# DA1469x register map
Vendor: Dialog; Series: DA1469x; File version: 1.2
CPU: CM33 r1p0, little endian, no MPU, FPU, 3 interrupt priority bits
Registers are 32-bit, read-write, reset 0x0 unless marked. A register's access mark holds for its fields unless they carry their own. Offsets are from the block's base; [hi:lo] are bit positions; {n}, {i} and the like mark numbered series.

## CRG_TOP — CRG_TOP registers
Base 0x50000000
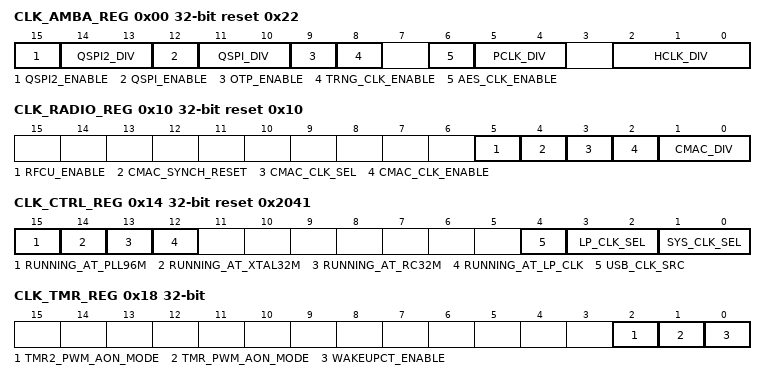
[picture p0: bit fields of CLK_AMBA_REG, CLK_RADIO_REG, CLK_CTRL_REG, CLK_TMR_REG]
0x00 CLK_AMBA_REG reset 0x22 — HCLK, PCLK, divider and clock gates
  [15] QSPI2_ENABLE — Clock enable for QSPI RAM controller
  [14:13] QSPI2_DIV — QSPI divider 00 = divide by 1 01 = divide by 2 10 = divide by 4 11 = divide by 8
  [12] QSPI_ENABLE — Clock enable for QSPI controller
  [11:10] QSPI_DIV — QSPI divider 00 = divide by 1 01 = divide by 2 10 = divide by 4 11 = divide by 8
  [9] OTP_ENABLE — Clock enable for OTP controller
  [8] TRNG_CLK_ENABLE — Clock enable for TRNG block
  [6] AES_CLK_ENABLE — Clock enable for AES crypto block
  [5:4] PCLK_DIV — APB interface clock, Cascaded with HCLK: 00 = divide hclk by 1 01 = divide hclk by 2 10 = divide hclk by 4 11 = divide hclk by 8
  [2:0] HCLK_DIV — AHB interface and microprocessor clock. Source clock divided by: 000 = divide hclk by 1 001 = divide hclk by 2 010 = divide hclk by 4 011 = divide hclk by 8 1xx = divide hclk by 16
0x10 CLK_RADIO_REG reset 0x10 — Radio PLL control register
  [5] RFCU_ENABLE — Enable the RF control Unit clock
  [4] CMAC_SYNCH_RESET — Force synchronous reset to CMAC core and Sleep Timer. Its effective only when both Radio and Timer Power Domains are powered and the clocks are enabled. CMAC CPU and CMAC registers, including the retained ones, will be reset. It should be kept in reset for enough time to make sure that it will be captured by CMAC, Low Power and APB clocks.
  [3] CMAC_CLK_SEL — Selects the clock source 1 = DIV1 clock 0 = DIVN clock
  [2] CMAC_CLK_ENABLE — Enables the clock
  [1:0] CMAC_DIV — Division factor for CMAC 0x0 = divide by 1 0x1 = divide by 2 0x2 = divide by 4 0x3 = divide by 8
0x14 CLK_CTRL_REG reset 0x2041 — Clock control register
  [15] RUNNING_AT_PLL96M ro — Indicates that the PLL96MHz clock is used as clock, and may not be switched off
  [14] RUNNING_AT_XTAL32M ro — Indicates that the XTAL32M clock is used as clock, and may not be switched off
  [13] RUNNING_AT_RC32M ro — Indicates that the RC32M clock is used as clock
  [12] RUNNING_AT_LP_CLK ro — Indicates that either the LP_CLK is being used as clock
  [4] USB_CLK_SRC — Selects the USB source clock 0 : PLL clock, divided by 2 1 : HCLK
  [3:2] LP_CLK_SEL — Sets the clock source of the LowerPower clock 0x0: RC32K 0x1: RCX 0x2: XTAL32K through the oscillator with an external Crystal. 0x3: XTAL32K through an external square wave generator (set PID of GPIO to FUNC_GPIO)
  [1:0] SYS_CLK_SEL — Selects the clock source. 0x0 : XTAL32M 0x1 : RC32M 0x2 : The Low Power clock is used 0x3 : The PLL96Mhz is used
0x18 CLK_TMR_REG — Clock control for the timers
  [2] TMR2_PWM_AON_MODE — Maps Timer2_pwm onto P1_06. This state is preserved during deep sleep, to allow PWM output on the pad during deep sleep.
  [1] TMR_PWM_AON_MODE — Maps Timer1_pwm onto P1_01 This state is preserved during deep sleep, to allow PWM output on the pad during deep sleep.
  [0] WAKEUPCT_ENABLE — Enables the clock
0x1C CLK_SWITCH2XTAL_REG — Switches clock from RC32M to XTAL32M
  [0] SWITCH2XTAL wo — When writing to this register, the clock switch will happen from RC32M to XTAL32M. If any other clock is selected than RC32M, the selection is discarded.
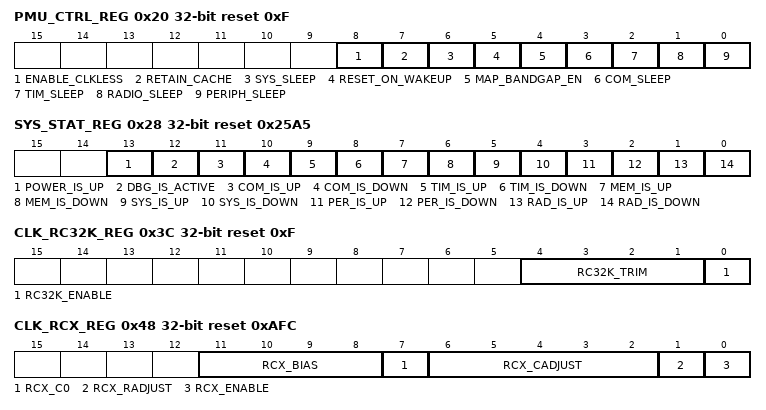
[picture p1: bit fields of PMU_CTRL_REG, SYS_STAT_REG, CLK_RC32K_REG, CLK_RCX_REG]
0x20 PMU_CTRL_REG reset 0xF — Power Management Unit control register
  [8] ENABLE_CLKLESS — Selects the clockless sleep mode. Wakeup is done asynchronously. When set to '1', the lp_clk is stopped during deep sleep, until a wakeup event (not debounced) is detected by the WAKUPCT block. When set to '0', the lp_clk continues running, so the MAC counters keep on running. This mode cannot be combined with regulated sleep, so keep SLEEP_TIMER=0 when using ENABLE_CLKLESS.
  [7] RETAIN_CACHE — Selects the retainability of the cache block during deep sleep. '1' is retainable, '0' is power gated
  [6] SYS_SLEEP — Put the System powerdomain (PD_SYS) in powerdown. If this bit is '1', and there is no pending IRQ in the PDC for the M33, the PD_SYS will be switched off. Wakeup should be handled by the PDC.
  [5] RESET_ON_WAKEUP — Perform a Hardware Reset after waking up. Booter will be started.
  [4] MAP_BANDGAP_EN — Setting this bit will: -map bandgap_enable to P0_25 -map (wokenup OR cmac_slp_timer_expire) to P0_16
  [3] COM_SLEEP — Put the Communications powerdomain (PD_COM) in powerdown
  [2] TIM_SLEEP — Put the Timers Powerdomain (PD_TIM) in powerdown.
  [1] RADIO_SLEEP — Put the digital part of the radio, including CMAC (PD_RAD) in powerdown
  [0] PERIPH_SLEEP — Put the peripherals power domain (PD_PER) in powerdown
0x28 SYS_STAT_REG reset 0x25A5 — System status register
  [13] POWER_IS_UP ro — Indicates that the Startup statemachine is finished, and all power regulation is in order. In UltraFastWakeup mode, the SW needs to wait for this signal before starting any heavy traffic.
  [12] DBG_IS_ACTIVE ro — Indicates that a debugger is attached.
  [11] COM_IS_UP ro — Indicates that PD_COM is functional
  [10] COM_IS_DOWN ro — Indicates that PD_COM is in power down
  [9] TIM_IS_UP ro — Indicates that PD_TIM is functional
  [8] TIM_IS_DOWN ro — Indicates that PD_TIM is in power down
  [7] MEM_IS_UP ro — Indicates that PD_MEM is functional
  [6] MEM_IS_DOWN ro — Indicates that PD_MEM is in power down
  [5] SYS_IS_UP ro — Indicates that PD_SYS is functional
  [4] SYS_IS_DOWN ro — Indicates that PD_SYS is in power down
  [3] PER_IS_UP ro — Indicates that PD_PER is functional
  [2] PER_IS_DOWN ro — Indicates that PD_PER is in power down
  [1] RAD_IS_UP ro — Indicates that PD_RAD is functional
  [0] RAD_IS_DOWN ro — Indicates that PD_RAD is in power down
0x3C CLK_RC32K_REG reset 0xF — 32 kHz RC oscillator register
  [4:1] RC32K_TRIM — 0000 = lowest frequency 0111 = default 1111 = highest frequency
  [0] RC32K_ENABLE — Enables the 32kHz RC oscillator
0x48 CLK_RCX_REG reset 0xAFC — RCX-oscillator control register
  [11:8] RCX_BIAS — LDO bias current. 0x0: minimum 0xF: maximum
  [7] RCX_C0 — Add unit capacitance to RC-time delay.
  [6:2] RCX_CADJUST — Adjust capacitance part of RC-time delay. 0x00: minimum capacitance 0x1F: maximum capacitance
  [1] RCX_RADJUST — Adjust resistance part of RC-time delay. Lower resistance increases power consumption. 0x0: maximum resistance 0x1: minimum resistance
  [0] RCX_ENABLE — Enable the RCX oscillator
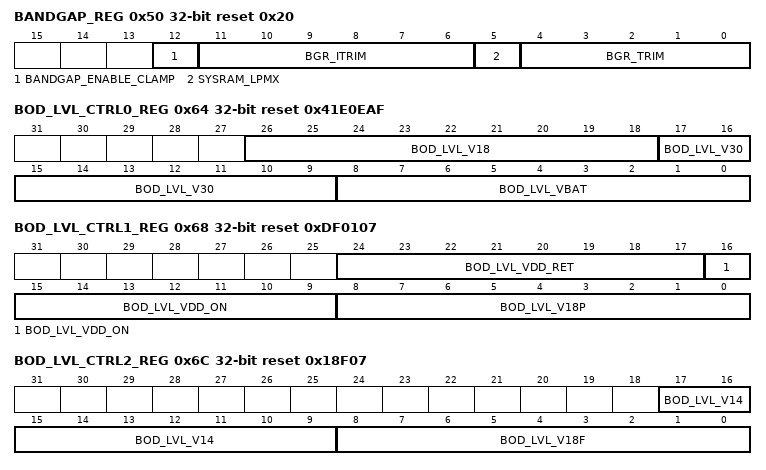
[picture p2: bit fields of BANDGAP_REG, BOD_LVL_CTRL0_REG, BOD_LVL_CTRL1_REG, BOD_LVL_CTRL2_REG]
0x50 BANDGAP_REG reset 0x20 — bandgap trimming
  [12] BANDGAP_ENABLE_CLAMP — Enables a supply clamp inside the bandgap that improves PSRR. Should be enabled by software after cold boot.
  [11:6] BGR_ITRIM — Current trimming for bias
  [5] SYSRAM_LPMX — RAM Transparent Light Sleep (TLS) Core Enable for System RAMs. Assert low to enable the TLS core feature, which will result in lower leakage current. In case VDD is below 0.81V, it is necessary to hold this pin high to maintain data retention.
  [4:0] BGR_TRIM — Trim register for bandgap
0x58 VBUS_IRQ_CLEAR_REG — Clear pending IRQ register
  [15:0] VBUS_IRQ_CLEAR wo — Writing any value to this register will reset the VBUS_IRQ line
0x64 BOD_LVL_CTRL0_REG reset 0x41E0EAF
  [26:18] BOD_LVL_V18 — Brown-out detection level for V18; disable the bod channel before adjusting the level setting. VTH_BOD = 1.2 * (BOD_LVL+1)/192
  [17:9] BOD_LVL_V30 — Brown-out detection level for V30; disable the bod channel before adjusting the level setting. VTH_BOD = 1.2 * (BOD_LVL+1)/192
  [8:0] BOD_LVL_VBAT — Brown-out detection level for VBAT; disable the bod channel before adjusting the level setting. VTH_BOD = 1.5*(1.2 * (BOD_LVL+1)/192)
0x68 BOD_LVL_CTRL1_REG reset 0xDF0107
  [24:17] BOD_LVL_VDD_RET — Brown-out detection level for VDD in sleep; disable the bod channel before adjusting the level setting. VTH_BOD = 1.2 * (BOD_LVL+1)/192
  [16:9] BOD_LVL_VDD_ON — Brown-out detection level for VDD in active; disable the bod channel before adjusting the level setting. VTH_BOD = 1.2 * (BOD_LVL+1)/192
  [8:0] BOD_LVL_V18P — Brown-out detection level for V18P; disable the bod channel before adjusting the level setting. VTH_BOD = 1.2 * (BOD_LVL+1)/192
0x6C BOD_LVL_CTRL2_REG reset 0x18F07
  [17:9] BOD_LVL_V14 — Brown-out detection level for V14; disable the bod channel before adjusting the level setting. VTH_BOD = 1.2 * (BOD_LVL+1)/192
  [8:0] BOD_LVL_V18F — Brown-out detection level for V18F; disable the bod channel before adjusting the level setting. VTH_BOD = 1.2 * (BOD_LVL+1)/192
0x70 P0_PAD_LATCH_REG reset 0x7FFFFFFF (reset mask 0x7FFFFFFF) — Control the state retention of the GPIO ports
  [31:0] P0_LATCH_EN — Direct write to the specific pad_latch_enable signal
0x74 P0_SET_PAD_LATCH_REG (reset mask 0x7FFFFFFF) — Control the state retention of the GPIO ports
  [31:0] P0_SET_LATCH_EN rw-once — Direct Set of the marked bits. Reading returns 0x0.
0x78 P0_RESET_PAD_LATCH_REG (reset mask 0x7FFFFFFF) — Control the state retention of the GPIO ports
  [31:0] P0_RESET_LATCH_EN — Direct Reset of the marked bits. Reading returns 0x0.
0x7C P1_PAD_LATCH_REG reset 0x7FFFFF — Control the state retention of the GPIO ports
  [22:0] P1_LATCH_EN — Direct write to the specific pad_latch_enable signal
0x80 P1_SET_PAD_LATCH_REG — Control the state retention of the GPIO ports
  [22:0] P1_SET_LATCH_EN rw-once — Direct Set of the marked bits. Reading returns 0x0.
0x84 P1_RESET_PAD_LATCH_REG — Control the state retention of the GPIO ports
  [22:0] P1_RESET_LATCH_EN — Direct Reset of the marked bits. Reading returns 0x0.
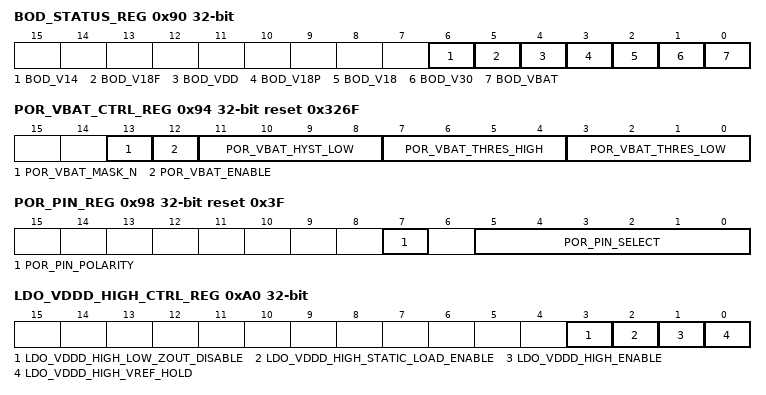
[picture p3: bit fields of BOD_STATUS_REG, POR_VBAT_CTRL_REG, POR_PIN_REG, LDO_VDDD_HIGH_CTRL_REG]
0x90 BOD_STATUS_REG
  [6] BOD_V14 ro — 1: below trigger level (BOD event) 0: above trigger level
  [5] BOD_V18F ro — 1: below trigger level (BOD event) 0: above trigger level
  [4] BOD_VDD ro — 1: below trigger level (BOD event) 0: above trigger level
  [3] BOD_V18P ro — 1: below trigger level (BOD event) 0: above trigger level
  [2] BOD_V18 ro — 1: below trigger level (BOD event) 0: above trigger level
  [1] BOD_V30 ro — 1: below trigger level (BOD event) 0: above trigger level
  [0] BOD_VBAT ro — 1: below trigger level (BOD event) 0: above trigger level
0x94 POR_VBAT_CTRL_REG reset 0x326F — Controls the POR on VBAT
  [13] POR_VBAT_MASK_N — Enables propagation of the generated POR
  [12] POR_VBAT_ENABLE — Enables generation of the POR
  [11:8] POR_VBAT_HYST_LOW — Controls hysteresis of POR. 20mV per step. Must be set to 0x2 when thres_ctrl_low is set to 0xf.
  [7:4] POR_VBAT_THRES_HIGH — High-side (PTAT) threshold contribution: Level --> Threshold 0x0 --> 1.25V 0x1 --> 1.27V 0x2 --> 1.29V 0x3 --> 1.31V 0x4 --> 1.44V 0x5 --> 1.49V 0x6 --> 1.53V 0x7 --> 1.58V 0x8 --> 1.63V 0x9 --> 1.68V 0xA --> 1.73V 0xB --> 1.78V0xC --> 1.83V0xD --> 1.87V0xE --> 1.92V 0xF --> 1.97V
  [3:0] POR_VBAT_THRES_LOW — Low-side (CTAT) threshold contribution Level --> Threshold 0xC --> 1.25V 0xC --> 1.27V 0xC --> 1.29V 0xC --> 1.31V 0x0 --> 1.44V 0x1 --> 1.49V 0x2 --> 1.53V 0x3 --> 1.58V 0x4 --> 1.63V 0x5 --> 1.68V 0x6 --> 1.73V 0x7 --> 1.78V 0x8 --> 1.83V 0x9 --> 1.87V 0xA --> 1.92V 0xB --> 1.97V 0xF --> 1.63V; use only with POR_VBAT_THRES_LOW=0x6 and POR_VBAT_THRES_HYST=0x2
0x98 POR_PIN_REG reset 0x3F — Selects a GPIO pin for POR generation
  [7] POR_PIN_POLARITY — 0: Active Low 1: Active High Note: This applies only for the GPIO pin. Reset pad is always active High
  [5:0] POR_PIN_SELECT — 0x00: P0_00 ... 0x1f: P0_31 0x20: P1_00 ... 0x36: P1_22 0x37 to 0x3E: reserved 0x3F: POR generation disabled
0x9C POR_TIMER_REG reset 0x18 — Time for POR to happen
  [6:0] POR_TIME — Time for the POReset to happen. Formula: Time = POR_TIME x 4096 x RC32 clock period Default value: ~3 seconds
0xA0 LDO_VDDD_HIGH_CTRL_REG — LDO control register
  [3] LDO_VDDD_HIGH_LOW_ZOUT_DISABLE — Disables the low Zout switch. The low Zout switch pulls the output of the LDO to ground. When 0, the output of the LDO is pulled to ground when the LDO is disabled. When 1, the output of the LDO remains floating when the LDO is disabled.
  [2] LDO_VDDD_HIGH_STATIC_LOAD_ENABLE — Enables a static load of approx. 10 uA at the output of the LDO VDDD_HIGH.
  [1] LDO_VDDD_HIGH_ENABLE — 0: LDO VDDD_HIGH off, 1: LDO VDDD_HIGH on.
  [0] LDO_VDDD_HIGH_VREF_HOLD — 0: Indicates that the reference input is tracked, 1: Indicates that the reference input is sampled.
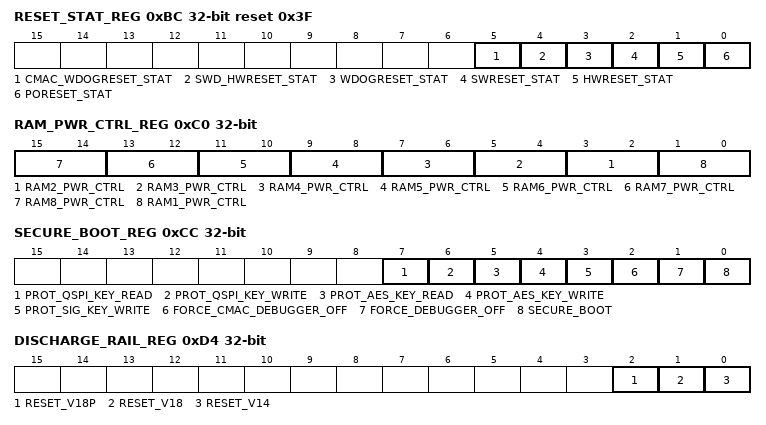
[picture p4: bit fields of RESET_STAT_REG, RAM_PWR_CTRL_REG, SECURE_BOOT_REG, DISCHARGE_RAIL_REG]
0xBC RESET_STAT_REG reset 0x3F — Reset status register
  [5] CMAC_WDOGRESET_STAT — Indicates that a CMAC-Watchdog timeout has happened. Note that it is also set when a POReset has happened.
  [4] SWD_HWRESET_STAT — Indicates that a write to SWD_RESET_REG has happened. Note that it is also set when a POReset has happened.
  [3] WDOGRESET_STAT — Indicates that a Watchdog timeout has happened. Note that it is also set when a POReset has happened.
  [2] SWRESET_STAT — Indicates that a SW Reset has happened
  [1] HWRESET_STAT — Indicates that a HW Reset has happened
  [0] PORESET_STAT — Indicates that a PowerOn Reset has happened. All bitfields of RESET_STAT_REG should be read (in order to check the source of reset) and then cleared to '0', allowing thus the HW to automatically set to '1' the proper bitfields during the next reset event.
0xC0 RAM_PWR_CTRL_REG — Control power state of System RAMS
  [2n-1:2n-2] RAM{n}_PWR_CTRL (n=2..8) — See description of RAM1_PWR_CTRL.
  [1:0] RAM1_PWR_CTRL — Power state control of the individual RAMs. May only change when the memory isn't accessed. When PD_MEM_IS_UP: 0x0: Normal operation 0x1: Normal operation 0x2: Retained (no access possible) 0x3: Off (memory content corrupted) When PD_MEM_IS_DOWN: 0x0: Retained 0x1: Off (memory content corrupted) 0x2: Retained 0x3: Off (memory content corrupted)
0xCC SECURE_BOOT_REG — Controls secure booting
  [7] PROT_QSPI_KEY_READ — This bit will permanently disable CPU read capability at OTP offset 0x00000B00 and for the complete segment
  [6] PROT_QSPI_KEY_WRITE — This bit will permanently disable ANY write capability at OTP offset 0x00000B00 and for the complete segment
  [5] PROT_AES_KEY_READ — This bit will permanently disable CPU read capability at OTP offset 0x00000A00 and for the complete segment
  [4] PROT_AES_KEY_WRITE — This bit will permanently disable ANY write capability at OTP offset 0x00000A00 and for the complete segment
  [3] PROT_SIG_KEY_WRITE — This bit will permanently disable ANY write capability at OTP offset 0x000008C0 and for the complete segment
  [2] FORCE_CMAC_DEBUGGER_OFF — This bit will permanently disable the CMAC debugger
  [1] FORCE_DEBUGGER_OFF — Follows the respective OTP flag value. Its value is updated by the BootROM code. 1: The system debugger SWD is totally disabled. 0: The system debugger is enabled with DEBUGGER_ENABLE
  [0] SECURE_BOOT — Follows the respective OTP flag value. Its value is updated by the BootROM code. 1: system is a secure system supporting secure boot 0: system is not supporting secure boot
0xD4 DISCHARGE_RAIL_REG — Immediate rail resetting. There is no LDO/DCDC gating
  [2] RESET_V18P — 1: Enables immediate discharging of the V18P rail. Note that the source is not disabled. 0: disable immediate discharging of the V18P rail. This bit is ORed with the automatic function controlled by PMU_RESET_RAIL_REG.RESET_V18P
  [1] RESET_V18 — 1: Enables immediate discharging of the V18 rail. Note that the source is not disabled. 0: disable immediate discharging of the V18 rail. This bit is ORed with the automatic function controlled by PMU_RESET_RAIL_REG.RESET_V18
  [0] RESET_V14 — 1: Enables immediate discharging of the V14 rail. Note that the source is not disabled. 0: disable immediate discharging of the V14 rail. This bit is ORed with the automatic function controlled by PMU_RESET_RAIL_REG.RESET_V14
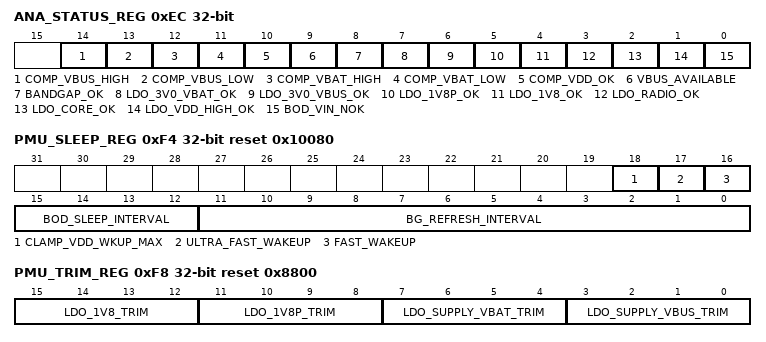
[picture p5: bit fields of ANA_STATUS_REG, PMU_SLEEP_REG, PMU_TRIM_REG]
0xEC ANA_STATUS_REG — Analog Signals Status Register
  [14] COMP_VBUS_HIGH ro — COMP_VBUS_HIGH = 1 -> VBUS > 4V
  [13] COMP_VBUS_LOW ro — COMP_VBUS_LOW = 1 -> VBUS > 3.4V
  [12] COMP_VBAT_HIGH ro — COMP_VBAT_HIGH =1 -> VBAT > 2.5V
  [11] COMP_VBAT_LOW ro — COMP_VBAT_LOW = 1 -> VBAT > 1.667V
  [10] COMP_VDD_OK ro — COMP_VDD_OK = 1 -> VDD > 1.125V
  [9] VBUS_AVAILABLE ro — High when VBUS > ( VBAT + 150 mV). Hysteresis is approx. 40 mV
  [8] BANDGAP_OK ro — When high bandgap is active
  [7] LDO_3V0_VBAT_OK ro — When high LDO_VBAT is active
  [6] LDO_3V0_VBUS_OK ro — When high LDO_VBUS is active
  [5] LDO_1V8P_OK ro — When high LDO_IO2 is active
  [4] LDO_1V8_OK ro — When high LDO_IO is active
  [3] LDO_RADIO_OK ro — When high LDO_RADIO is active
  [2] LDO_CORE_OK ro — When high LDO_CORE(LDO1V2) is active
  [1] LDO_VDD_HIGH_OK ro — When high the ADC LDO is active. This LDO also supplies part of the LRA
  [0] BOD_VIN_NOK ro — General output of the BOD to indicate that one of the monitored inputs is below the trigger-level.
0xF4 PMU_SLEEP_REG reset 0x10080 — Configures the sleep/wakeup strategy
  [18] CLAMP_VDD_WKUP_MAX — Forces the VDD clamp voltage to its maximum value when waking up from sleep.
  [17] ULTRA_FAST_WAKEUP — Allows the core to start running on the RC32M while the PMU is still waiting for supplies to settle to the final value. Only use in combination with FAST_WAKEUP and 0.9 V on VDD during sleep.
  [16] FAST_WAKEUP — Speeds up the wakeup process by enabling all LDOs simultaneously instead of in staggered order. Only use if all voltages have been retained during sleep.
  [15:12] BOD_SLEEP_INTERVAL — This is a value defining the interval every which Brown Out Detection is activated to check on the power rails voltage. The value represents BG_REFRESH_INTERVALs
  [11:0] BG_REFRESH_INTERVAL — This is a value defining the interval every which the Bandgap will be activated for refresh. The value represents ticks of lp_clk/64 e.g. 30,5 us * 64 = 1,9 ms.
0xF8 PMU_TRIM_REG reset 0x8800 — LDO trimming register
  [15:12] LDO_1V8_TRIM — Trim setting for LDO_1V8 Unsigned binary notation, trim range ±10 percent
  [11:8] LDO_1V8P_TRIM — Trim setting for LDO_1V8P Unsigned binary notation, trim range ±10 percent
  [7:4] LDO_SUPPLY_VBAT_TRIM — Trim setting for LDO_SUPPLY_VBAT Sign-magnitude notation, trim range ±10 percent
  [3:0] LDO_SUPPLY_VBUS_TRIM — Trim setting for LDO_SUPPLY_VBUS Sign-magnitude notation, trim range ±10 percent
